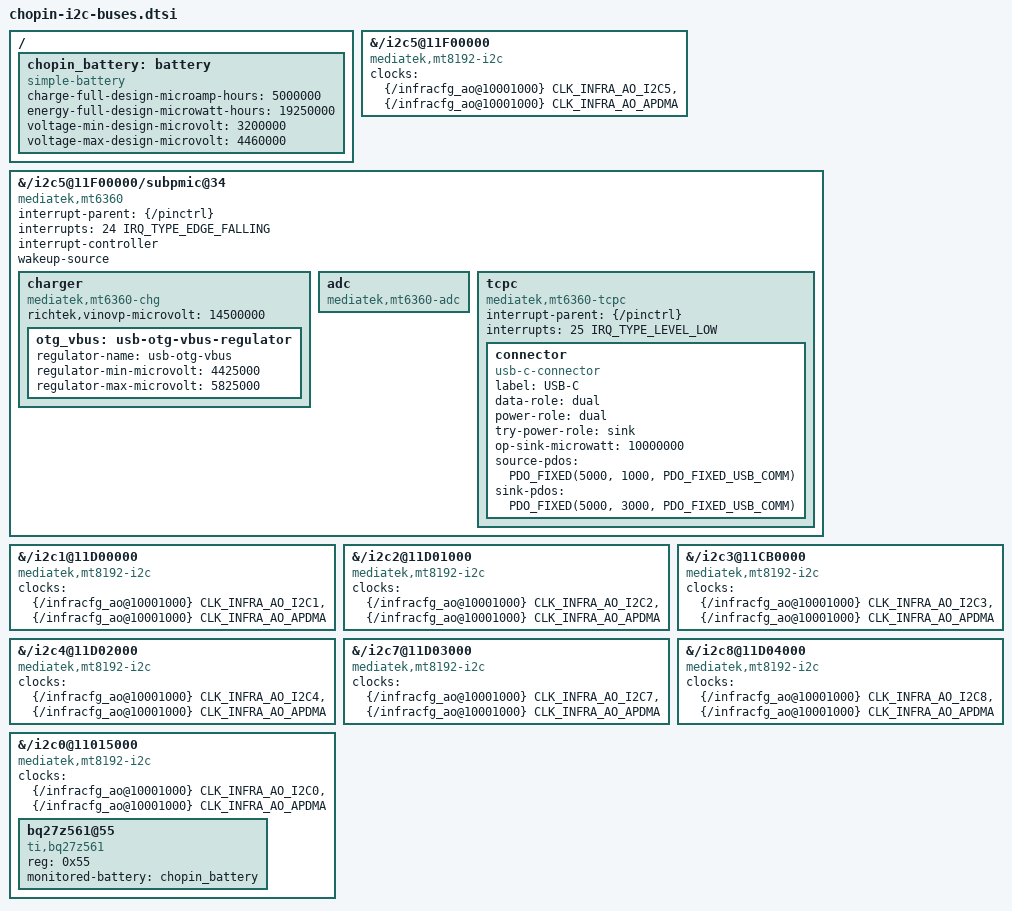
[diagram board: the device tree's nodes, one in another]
// SPDX-License-Identifier: GPL-2.0-only
/*
 * chopin: the other i2c buses and the sub-PMIC.
 */

&{/i2c5@11F00000} {
	compatible = "mediatek,mt8192-i2c";
	clocks = <&{/infracfg_ao@10001000} CLK_INFRA_AO_I2C5>,
		 <&{/infracfg_ao@10001000} CLK_INFRA_AO_APDMA>;
	clock-names = "main", "dma";
};

/*
 * Repoint the node that already owns 0x34 rather than adding a second one - two
 * clients at the same address is exactly the -EBUSY that a first attempt on the
 * wrong bus produced.
 *
 * Interrupts: PMU IRQB on GPIO 24 and the Type-C controller's on GPIO 25, which
 * the base tree itself confirms (mt6360_pmu_dts has intr_gpio_num = 24, the PD
 * node has 25) and which now resolve, because the pin controller finally binds.
 * charger/adc get their interrupts from the MFD's cell resources; only the
 * Type-C child needs its own node.
 */
&{/i2c5@11F00000/subpmic@34} {
	compatible = "mediatek,mt6360";
	interrupt-parent = <&{/pinctrl}>;
	interrupts = <24 IRQ_TYPE_EDGE_FALLING>;
	interrupt-names = "IRQB";
	interrupt-controller;
	#interrupt-cells = <0x01>;	/* binding: the cell is the IRQ number */
	wakeup-source;

	charger {
		compatible = "mediatek,mt6360-chg";
		/* the vendor's max_charger_voltage for this board */
		richtek,vinovp-microvolt = <14500000>;

		/*
		 * OTG boost: the 5 V a host has to put on the port.  The charger
		 * driver registers it (mt6360_otg_rdesc.of_match is this node's
		 * name) and the USB controller below names it as its vbus-supply,
		 * so switching the port to host enables it and switching back
		 * disables it again.
		 */
		otg_vbus: usb-otg-vbus-regulator {
			regulator-name = "usb-otg-vbus";
			regulator-min-microvolt = <4425000>;
			regulator-max-microvolt = <5825000>;
		};
	};

	adc {
		compatible = "mediatek,mt6360-adc";
		#io-channel-cells = <0x01>;
	};

	tcpc {
		compatible = "mediatek,mt6360-tcpc";
		interrupt-parent = <&{/pinctrl}>;
		interrupts = <25 IRQ_TYPE_LEVEL_LOW>;
		interrupt-names = "PD_IRQB";

		connector {
			compatible = "usb-c-connector";
			label = "USB-C";
			data-role = "dual";
			power-role = "dual";
			try-power-role = "sink";
			op-sink-microwatt = <10000000>;
			source-pdos = <PDO_FIXED(5000, 1000, PDO_FIXED_USB_COMM)>;
			sink-pdos = <PDO_FIXED(5000, 3000, PDO_FIXED_USB_COMM)>;
		};
	};
};

/* The remaining buses get the same two-line treatment, so a scan can see the
 * whole board instead of two controllers.  Their bus clocks are the ones the
 * mt6893 clock header defines; i2c9 and above are not needed for charging. */
&{/i2c1@11D00000} {
	compatible = "mediatek,mt8192-i2c";
	clocks = <&{/infracfg_ao@10001000} CLK_INFRA_AO_I2C1>,
		 <&{/infracfg_ao@10001000} CLK_INFRA_AO_APDMA>;
	clock-names = "main", "dma";
};

&{/i2c2@11D01000} {
	compatible = "mediatek,mt8192-i2c";
	clocks = <&{/infracfg_ao@10001000} CLK_INFRA_AO_I2C2>,
		 <&{/infracfg_ao@10001000} CLK_INFRA_AO_APDMA>;
	clock-names = "main", "dma";
};

&{/i2c3@11CB0000} {
	compatible = "mediatek,mt8192-i2c";
	clocks = <&{/infracfg_ao@10001000} CLK_INFRA_AO_I2C3>,
		 <&{/infracfg_ao@10001000} CLK_INFRA_AO_APDMA>;
	clock-names = "main", "dma";
};

&{/i2c4@11D02000} {
	compatible = "mediatek,mt8192-i2c";
	clocks = <&{/infracfg_ao@10001000} CLK_INFRA_AO_I2C4>,
		 <&{/infracfg_ao@10001000} CLK_INFRA_AO_APDMA>;
	clock-names = "main", "dma";
};

&{/i2c7@11D03000} {
	compatible = "mediatek,mt8192-i2c";
	clocks = <&{/infracfg_ao@10001000} CLK_INFRA_AO_I2C7>,
		 <&{/infracfg_ao@10001000} CLK_INFRA_AO_APDMA>;
	clock-names = "main", "dma";
};

&{/i2c8@11D04000} {
	compatible = "mediatek,mt8192-i2c";
	clocks = <&{/infracfg_ao@10001000} CLK_INFRA_AO_I2C8>,
		 <&{/infracfg_ao@10001000} CLK_INFRA_AO_APDMA>;
	clock-names = "main", "dma";
};

&{/i2c0@11015000} {
	compatible = "mediatek,mt8192-i2c";
	clocks = <&{/infracfg_ao@10001000} CLK_INFRA_AO_I2C0>,
		 <&{/infracfg_ao@10001000} CLK_INFRA_AO_APDMA>;
	clock-names = "main", "dma";

	/*
	 * The battery gauge is a TI BQ27Z561, not the PMIC's own gauge: the vendor
	 * tree disables mtk's (bat_gm30 { DISABLE_MTKBATTERY; use-ti-gauge; }) and
	 * talks to this chip instead.  Mainline's bq27xxx driver supports it, and
	 * it is what makes battery voltage/current/capacity visible at all.
	 * charge-full-design is the vendor's own bq,charge-full-design value.
	 */
	bq27z561@55 {
		compatible = "ti,bq27z561";
		reg = <0x55>;
		monitored-battery = <&chopin_battery>;
	};
};

/* The cell, as the vendor describes it. */
/ {
	chopin_battery: battery {
		compatible = "simple-battery";
		charge-full-design-microamp-hours = <5000000>;
		energy-full-design-microwatt-hours = <19250000>;
		voltage-min-design-microvolt = <3200000>;
		voltage-max-design-microvolt = <4460000>;
	};
};
